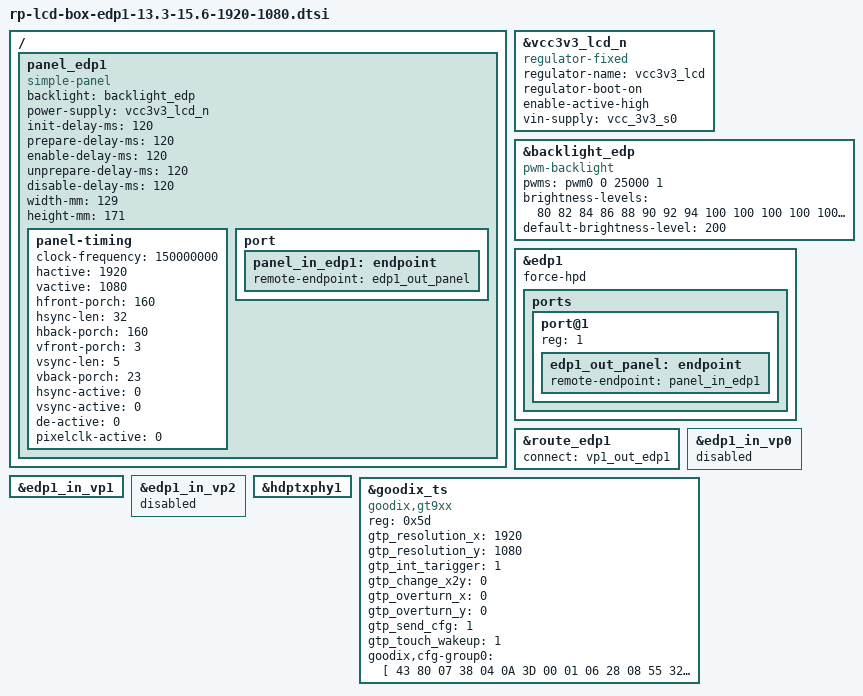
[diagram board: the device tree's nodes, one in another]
/ {


    panel_edp1 {
        compatible = "simple-panel";
        backlight = <&backlight_edp>;
        power-supply = <&vcc3v3_lcd_n>;
        init-delay-ms = <120>;
        prepare-delay-ms = <120>;
        enable-delay-ms = <120>;
        unprepare-delay-ms = <120>;
        disable-delay-ms = <120>;
        width-mm = <129>;
        height-mm = <171>;

        panel-timing {
                        clock-frequency = <150000000>;
                        hactive = <1920>;
                        vactive = <1080>;
                        hfront-porch = <160>;
                        hsync-len = <32>;
                        hback-porch = <160>;
                        vfront-porch = <3>;
                        vsync-len = <5>;
                        vback-porch = <23>;
                        hsync-active = <0>;
                        vsync-active = <0>;
                        de-active = <0>;
                        pixelclk-active = <0>;
        };

        port {
            panel_in_edp1: endpoint {
                remote-endpoint = <&edp1_out_panel>;
            };
        };
    };

};
&vcc3v3_lcd_n {
  compatible = "regulator-fixed";
  regulator-name = "vcc3v3_lcd";
  regulator-boot-on;
  enable-active-high;
  vin-supply = <&vcc_3v3_s0>;
};



&backlight_edp {
        compatible = "pwm-backlight";
        pwms = <&pwm0 0 25000 1>;
        status = "okay";
        brightness-levels = <
            80 82 84 86 88 90 92 94
            100 100 100 100 100 100 100 100
            110 110 110 110 110 110 110 110
            120 120 120 120 120 120 120 120
            130 130 130 130 130 130 130 130
            140 150 150 150 150 150 150 150
            170 170 170 170 170 170 170 170
            170 170 170 170 170 170 170 170
            180 180 180 180 180 180 180 180
            180 180 180 180 180 180 180 180
            190 190 190 190 190 190 190 190
            190 190 190 190 190 190 190 190
            200 200 200 200 200 200 200 200
            200 200 200 200 200 200 200 200
            200 200 200 200 200 200 200 200
            200 200 200 200 200 200 200 200
            200 200 200 200 200 200 200 200
            200 200 200 200 200 200 200 200
            200 200 200 200 200 200 200 200
            210 210 210 210 210 210 210 210
            220 220 220 220 220 220 220 220
            220 220 220 220 220 220 220 220
            220 220 220 220 220 220 220 220
            230 230 230 230 230 230 230 230
            230 230 230 230 230 230 230 230
            230 230 230 230 230 230 230 230
            240 240 240 240 240 240 240 240
            240 240 240 240 240 240 240 240
            240 240 240 240 240 240 240 240
            240 240 240 240 240 240 240 240
            240 241 242 243 244 245 246 247
            248 249 250 251 252 253 254 255
        >;
        default-brightness-level = <200>;
    };

&edp1 {
    force-hpd;
    status = "okay";

    ports {
        port@1 {
            reg = <1>;

            edp1_out_panel: endpoint {
                remote-endpoint = <&panel_in_edp1>;
            };
        };
    };
};

&route_edp1 {
    status = "okay";
    connect = <&vp1_out_edp1>;
};


&edp1_in_vp0 {
    status = "disabled";
};

&edp1_in_vp1 {
    status = "okay";
};

&edp1_in_vp2 {
    status = "disabled";
};

&hdptxphy1 {
    status = "okay";
};


&goodix_ts {
        status = "okay";
        compatible = "goodix,gt9xx";
        reg = <0x5d>;
        gtp_resolution_x = <1920>;
        gtp_resolution_y = <1080>;
        gtp_int_tarigger = <1>;
        gtp_change_x2y = <0>;
        gtp_overturn_x = <0>;
        gtp_overturn_y = <0>;
        gtp_send_cfg = <1>;
        gtp_touch_wakeup = <1>;

        goodix,cfg-group0 = [
         43 80 07 38 04 0A 3D 00 01 06
         28 08 55 32 03 05 00 00 00 00
         00 00 06 18 1A 1E 14 95 35 FF
         2D 2F A6 0F 00 00 00 01 03 2C
         00 00 00 00 00 00 00 00 00 00
         00 2D 5A 94 D0 42 00 08 00 04
         79 30 00 6E 37 00 65 3F 00 5D
         49 00 57 54 00 57 00 00 00 00
         00 00 00 00 00 00 00 00 00 00
         00 00 00 00 00 00 00 00 00 00
         00 00 00 00 00 00 00 00 00 00
         00 00 1D 1C 1B 1A 19 18 17 16
         15 14 13 12 11 10 0F 0E 0D 0C
         0B 0A 09 08 07 06 05 04 03 02
         01 00 00 01 02 03 04 05 06 07
         08 09 0A 0B 0C 0D 0E 0F 10 11
         12 13 14 15 16 17 18 19 1B 1C
         1D 1E 1F 20 21 22 23 24 25 26
         27 28 29 2A 86 01
        ];
};
